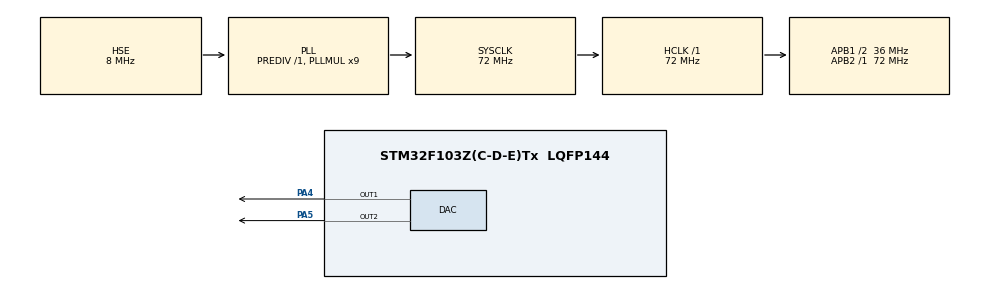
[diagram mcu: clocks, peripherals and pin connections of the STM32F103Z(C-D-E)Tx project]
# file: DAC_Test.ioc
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Mcu.Family=STM32F1
Mcu.Name=STM32F103Z(C-D-E)Tx
Mcu.Package=LQFP144
NVIC.PriorityGroup=NVIC_PRIORITYGROUP_4
NVIC.TIM2_IRQn=true\:0\:0\:false\:false\:true\:true\:true
OSC_IN.Mode=HSE-External-Oscillator
OSC_IN.Signal=RCC_OSC_IN
OSC_OUT.Mode=HSE-External-Oscillator
OSC_OUT.Signal=RCC_OSC_OUT
PA4.Signal=COMP_DAC1_group
PA5.Signal=COMP_DAC2_group
ProjectManager.HeapSize=0x200
ProjectManager.StackSize=0x400
ProjectManager.TargetToolchain=MDK-ARM V5
RCC.AHBFreq_Value=72000000
RCC.APB1CLKDivider=RCC_HCLK_DIV2
RCC.APB1Freq_Value=36000000
RCC.APB1TimFreq_Value=72000000
RCC.APB2Freq_Value=72000000
RCC.APB2TimFreq_Value=72000000
RCC.HCLKFreq_Value=72000000
RCC.PLLMUL=RCC_PLL_MUL9
RCC.PLLSourceVirtual=RCC_PLLSOURCE_HSE
RCC.SYSCLKFreq_VALUE=72000000
RCC.SYSCLKSource=RCC_SYSCLKSOURCE_PLLCLK
RCC.USBFreq_Value=72000000
SH.COMP_DAC1_group.0=DAC_OUT1,DAC_OUT1
SH.COMP_DAC2_group.0=DAC_OUT2,DAC_OUT2
TIM2.AutoReloadPreload=TIM_AUTORELOAD_PRELOAD_ENABLE
TIM2.Period=599
TIM2.Prescaler=59
VP_SYS_VS_ND.Mode=No_Debug
VP_TIM2_VS_ClockSourceINT.Mode=Internal
board=custom

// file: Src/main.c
/* USER CODE BEGIN Header */
/**
  ******************************************************************************
  * @file           : main.c
  * @brief          : Main program body
  ******************************************************************************
  * @attention
  *
  * <h2><center>&copy; Copyright (c) 2021 STMicroelectronics.
  * All rights reserved.</center></h2>
  *
  * This software component is licensed by ST under BSD 3-Clause license,
  * the "License"; You may not use this file except in compliance with the
  * License. You may obtain a copy of the License at:
  *                        opensource.org/licenses/BSD-3-Clause
  *
  ******************************************************************************
  */
/* USER CODE END Header */

#include "main.h"

DAC_HandleTypeDef hdac;

TIM_HandleTypeDef htim2;

void SystemClock_Config(void);
static void MX_GPIO_Init(void);
static void MX_DAC_Init(void);
static void MX_TIM2_Init(void);

/* USER CODE BEGIN 0 */
int i=1;
/* USER CODE END 0 */

int main(void)
{

  /* MCU Configuration--------------------------------------------------------*/

  /* Reset of all peripherals, Initializes the Flash interface and the Systick. */
  HAL_Init();

  /* Configure the system clock */
  SystemClock_Config();

  /* Initialize all configured peripherals */
  MX_GPIO_Init();
  MX_DAC_Init();
  MX_TIM2_Init();
  /* USER CODE BEGIN 2 */

HAL_DAC_Start(&hdac,DAC_CHANNEL_1); //??DAC??a
HAL_DAC_Start(&hdac,DAC_CHANNEL_2); //??DAC??a
HAL_TIM_Base_Start_IT(&htim2); //?????2????
  /* USER CODE END 2 */

  /* Infinite loop */
  while (1)
  {

  }
}

void SystemClock_Config(void)
{
  RCC_OscInitTypeDef RCC_OscInitStruct = {0};
  RCC_ClkInitTypeDef RCC_ClkInitStruct = {0};

  /** Initializes the CPU, AHB and APB busses clocks
  */
  RCC_OscInitStruct.OscillatorType = RCC_OSCILLATORTYPE_HSE;
  RCC_OscInitStruct.HSEState = RCC_HSE_ON;
  RCC_OscInitStruct.HSEPredivValue = RCC_HSE_PREDIV_DIV1;
  RCC_OscInitStruct.HSIState = RCC_HSI_ON;
  RCC_OscInitStruct.PLL.PLLState = RCC_PLL_ON;
  RCC_OscInitStruct.PLL.PLLSource = RCC_PLLSOURCE_HSE;
  RCC_OscInitStruct.PLL.PLLMUL = RCC_PLL_MUL9;
  if (HAL_RCC_OscConfig(&RCC_OscInitStruct) != HAL_OK)
  {
    Error_Handler();
  }
  /** Initializes the CPU, AHB and APB busses clocks
  */
  RCC_ClkInitStruct.ClockType = RCC_CLOCKTYPE_HCLK|RCC_CLOCKTYPE_SYSCLK
                              |RCC_CLOCKTYPE_PCLK1|RCC_CLOCKTYPE_PCLK2;
  RCC_ClkInitStruct.SYSCLKSource = RCC_SYSCLKSOURCE_PLLCLK;
  RCC_ClkInitStruct.AHBCLKDivider = RCC_SYSCLK_DIV1;
  RCC_ClkInitStruct.APB1CLKDivider = RCC_HCLK_DIV2;
  RCC_ClkInitStruct.APB2CLKDivider = RCC_HCLK_DIV1;

  if (HAL_RCC_ClockConfig(&RCC_ClkInitStruct, FLASH_LATENCY_2) != HAL_OK)
  {
    Error_Handler();
  }
}

static void MX_DAC_Init(void)
{

  DAC_ChannelConfTypeDef sConfig = {0};

  /** DAC Initialization
  */
  hdac.Instance = DAC;
  if (HAL_DAC_Init(&hdac) != HAL_OK)
  {
    Error_Handler();
  }
  /** DAC channel OUT1 config
  */
  sConfig.DAC_Trigger = DAC_TRIGGER_NONE;
  sConfig.DAC_OutputBuffer = DAC_OUTPUTBUFFER_ENABLE;
  if (HAL_DAC_ConfigChannel(&hdac, &sConfig, DAC_CHANNEL_1) != HAL_OK)
  {
    Error_Handler();
  }
  /** DAC channel OUT2 config
  */
  if (HAL_DAC_ConfigChannel(&hdac, &sConfig, DAC_CHANNEL_2) != HAL_OK)
  {
    Error_Handler();
  }

}

static void MX_TIM2_Init(void)
{

  TIM_ClockConfigTypeDef sClockSourceConfig = {0};
  TIM_MasterConfigTypeDef sMasterConfig = {0};

  htim2.Instance = TIM2;
  htim2.Init.Prescaler = 59;
  htim2.Init.CounterMode = TIM_COUNTERMODE_UP;
  htim2.Init.Period = 599;
  htim2.Init.ClockDivision = TIM_CLOCKDIVISION_DIV1;
  htim2.Init.AutoReloadPreload = TIM_AUTORELOAD_PRELOAD_ENABLE;
  if (HAL_TIM_Base_Init(&htim2) != HAL_OK)
  {
    Error_Handler();
  }
  sClockSourceConfig.ClockSource = TIM_CLOCKSOURCE_INTERNAL;
  if (HAL_TIM_ConfigClockSource(&htim2, &sClockSourceConfig) != HAL_OK)
  {
    Error_Handler();
  }
  sMasterConfig.MasterOutputTrigger = TIM_TRGO_RESET;
  sMasterConfig.MasterSlaveMode = TIM_MASTERSLAVEMODE_DISABLE;
  if (HAL_TIMEx_MasterConfigSynchronization(&htim2, &sMasterConfig) != HAL_OK)
  {
    Error_Handler();
  }

}

static void MX_GPIO_Init(void)
{

  /* GPIO Ports Clock Enable */
  __HAL_RCC_GPIOA_CLK_ENABLE();

}

/* USER CODE BEGIN 4 */
void HAL_TIM_PeriodElapsedCallback(TIM_HandleTypeDef *htim)
{
		if(htim == &htim2){
				if(i<=40){
						HAL_DAC_SetValue(&hdac,DAC_CHANNEL_1,DAC_ALIGN_12B_R,i*100);
						HAL_DAC_SetValue(&hdac,DAC_CHANNEL_2,DAC_ALIGN_12B_R,3000-i*i);
				}
				if(i>40){
						HAL_DAC_SetValue(&hdac,DAC_CHANNEL_1,DAC_ALIGN_12B_R,4000-(i-40)*100);
						HAL_DAC_SetValue(&hdac,DAC_CHANNEL_2,DAC_ALIGN_12B_R,0);
				}
		}
		i++;
		if(i>80)i=1;
}

/* USER CODE END 4 */

void Error_Handler(void)
{
}

/************************ (C) COPYRIGHT STMicroelectronics *****END OF FILE****/
